VERSION ""

NS_ :

BS_:

BU_:

BO_ 2566521342 CLSpnp_soc100: 2 Vector__XXX
 SG_ DoorState : 0|3@1+ (1,0) [0|7] "-" Vector__XXX
 SG_ LockStateReq : 3|2@1+ (1,0) [0|3] "" Vector__XXX

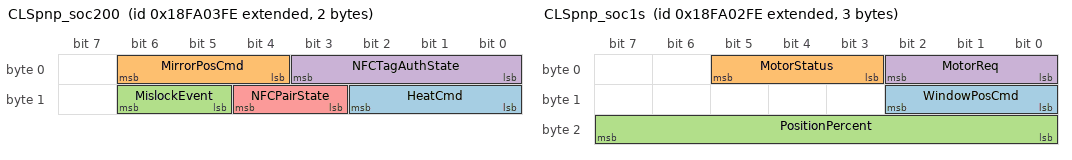
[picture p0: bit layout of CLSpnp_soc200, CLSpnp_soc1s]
BO_ 2566521854 CLSpnp_soc200: 2 Vector__XXX
 SG_ HeatCmd : 8|3@1+ (1,0) [0|7] "" Vector__XXX
 SG_ MirrorPosCmd : 4|3@1+ (1,0) [0|7] "" Vector__XXX
 SG_ MislockEvent : 13|2@1+ (1,0) [0|0] "" Vector__XXX
 SG_ NFCTagAuthState : 0|4@1+ (1,0) [0|0] "" Vector__XXX
 SG_ NFCPairState : 11|2@1+ (1,0) [0|0] "" Vector__XXX

BO_ 2365194494 CLSpnp_100: 9 Vector__XXX
 SG_ LockStateReq : 55|2@1+ (1,0) [0|3] "" Vector__XXX
 SG_ MotorStatus : 57|3@1+ (1,0) [0|0] "" Vector__XXX
 SG_ HallSensorSpeed : 32|23@1- (0.0005,0) [-2097.152|2097.1515] "rad/sec" Vector__XXX
 SG_ HallSensorCount : 0|32@1- (1,0) [-2147483648|2147483647] "" Vector__XXX
 SG_ LatchStateReq : 63|2@1+ (1,0) [0|3] "-" Vector__XXX
 SG_ DoorState : 60|3@1+ (1,0) [0|7] "-" Vector__XXX

BO_ 2566521598 CLSpnp_soc1s: 3 Vector__XXX
 SG_ WindowPosCmd : 8|3@1+ (1,0) [0|7] "" Vector__XXX
 SG_ MotorStatus : 3|3@1+ (1,0) [0|0] "" Vector__XXX
 SG_ PositionPercent : 16|8@1+ (1,0) [0|255] "" Vector__XXX
 SG_ MotorReq : 0|3@1+ (1,0) [0|7] "" Vector__XXX

CM_ BO_ 2566521598 "Cab Door Control
This message requests or commands the cabin windows";
CM_ SG_ 2566521598 WindowPosCmd "Commands position change of the right rear window.

000 = Window move up
001 = Window move down
010 = Window auto up
011 = Window auto down
100 = Reserved
101 = Reserved
110 = Reserved
111 = Take no action";
BA_DEF_  "DBName" STRING ;
BA_DEF_  "BusType" STRING ;
BA_DEF_  "ProtocolType" STRING ;
BA_DEF_ SG_  "GenSigStartValue" INT 0 2147483647;
BA_DEF_ BO_  "SendOnChange" ENUM  "No","Yes";
BA_DEF_ BO_  "GenMsgDelayTime" INT 0 1000;
BA_DEF_ BO_  "GenMsgSendType" ENUM  "cyclic","NotUsed","NotUsed","NotUsed","NotUsed","NotUsed","NotUsed","IfActive","noMsgSendType";
BA_DEF_ BO_  "GenMsgCycleTime" INT 0 3600000;
BA_DEF_ BO_  "VFrameFormat" ENUM  "StandardCAN","ExtendedCAN","reserved","J1939PG";
BA_DEF_DEF_  "DBName" "";
BA_DEF_DEF_  "BusType" "";
BA_DEF_DEF_  "ProtocolType" "";
BA_DEF_DEF_  "GenSigStartValue" 0;
BA_DEF_DEF_  "SendOnChange" "";
BA_DEF_DEF_  "GenMsgDelayTime" 0;
BA_DEF_DEF_  "GenMsgSendType" "";
BA_DEF_DEF_  "GenMsgCycleTime" 0;
BA_DEF_DEF_  "VFrameFormat" "";
BA_ "BusType" "CAN";
BA_ "ProtocolType" "J1939";
BA_ "DBName" "CLS_pnp";
BA_ "GenMsgCycleTime" BO_ 2566521342 100;
BA_ "GenMsgSendType" BO_ 2566521342 0;
BA_ "SendOnChange" BO_ 2566521342 1;
BA_ "VFrameFormat" BO_ 2566521342 3;
BA_ "GenMsgCycleTime" BO_ 2566521854 200;
BA_ "GenMsgSendType" BO_ 2566521854 0;
BA_ "SendOnChange" BO_ 2566521854 1;
BA_ "VFrameFormat" BO_ 2566521854 3;
BA_ "SendOnChange" BO_ 2365194494 0;
BA_ "GenMsgSendType" BO_ 2365194494 0;
BA_ "GenMsgCycleTime" BO_ 2365194494 100;
BA_ "VFrameFormat" BO_ 2365194494 3;
BA_ "GenMsgCycleTime" BO_ 2566521598 1000;
BA_ "GenMsgSendType" BO_ 2566521598 0;
BA_ "GenMsgDelayTime" BO_ 2566521598 100;
BA_ "SendOnChange" BO_ 2566521598 1;
BA_ "VFrameFormat" BO_ 2566521598 3;
BA_ "GenSigStartValue" SG_ 2566521342 LockStateReq 1;
BA_ "GenSigStartValue" SG_ 2365194494 LockStateReq 3;
BA_ "GenSigStartValue" SG_ 2566521598 WindowPosCmd 7;
VAL_ 2566521342 DoorState 7 "Not Available" 6 "Error" 2 "Closed" 1 "Ajared" 0 "Opened" ;
VAL_ 2566521342 LockStateReq 3 "Not Available" 2 "Error" 1 "Lock" 0 "Unlock" ;
VAL_ 2566521854 HeatCmd 7 "NA" 6 "Error" 2 "HeatOff" 1 "HeatOn" 0 "NoAction" ;
VAL_ 2566521854 MirrorPosCmd 4 "MoveRight" 3 "MoveLeft" 2 "MoveDw" 1 "MoveUp" 0 "NoAction" ;
VAL_ 2566521854 MislockEvent 3 "NA" 2 "Error" 1 "LockFail" 0 "NoFail" ;
VAL_ 2566521854 NFCTagAuthState 15 "defNoValidKey" 14 "tamperingAttempt" 13 "keyID_13" 12 "keyID_12" 11 "keyID_11" 10 "keyID_10" 9 "keyID_09" 8 "keyID_08" 7 "keyID_07" 6 "keyID_06" 5 "keyID_05" 4 "keyID_04" 3 "keyID_03" 2 "keyID_02" 1 "keyID_01" 0 "noValidKey" ;
VAL_ 2566521854 NFCPairState 3 "noActiveSession" 2 "authCommandError" 1 "authCmdSuccessful" 0 "noActiveAuthSession" ;
VAL_ 2365194494 LockStateReq 3 "Not Available" 2 "Error" 1 "Lock" 0 "Unlock" ;
VAL_ 2365194494 MotorStatus 7 "Not available" 6 "Error" 5 "Unknown" 4 "Closing" 3 "Opening" 2 "Intermediate" 1 "Closed" 0 "Open" ;
VAL_ 2365194494 LatchStateReq 3 "Not Available" 2 "DoubleLock" 1 "Unlatch" 0 "Inactive" ;
VAL_ 2365194494 DoorState 7 "Not Available" 6 "Error" 2 "Closed" 1 "Ajared" 0 "Opened" ;
VAL_ 2566521598 WindowPosCmd 7 "Take no action" 6 "Reserved" 5 "Reserved" 4 "Reserved" 3 "Window auto down" 2 "Window auto up" 1 "Window move down" 0 "Window move up" ;
VAL_ 2566521598 MotorStatus 7 "Not available" 6 "Error" 5 "Unknown" 4 "Closing" 3 "Opening" 2 "Intermediate" 1 "Closed" 0 "Open" ;
VAL_ 2566521598 MotorReq 6 "Calibration" 7 "Not available" 3 "Close" 2 "Open" 1 "Stop" 0 "Disable" ;
